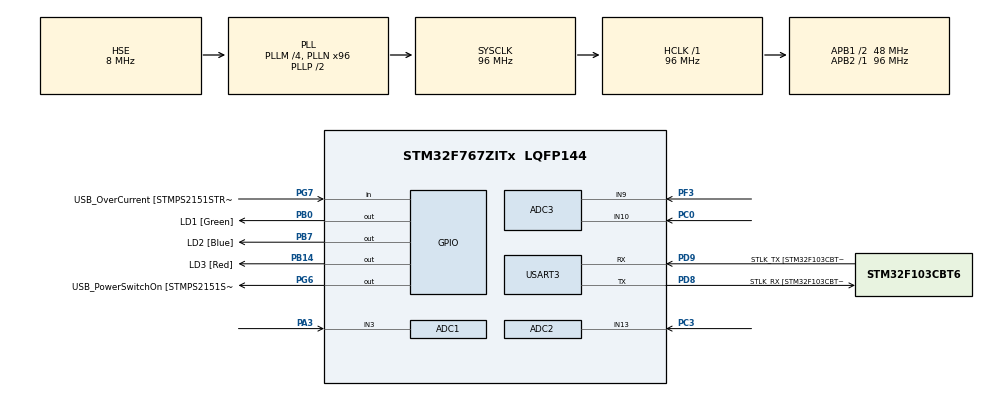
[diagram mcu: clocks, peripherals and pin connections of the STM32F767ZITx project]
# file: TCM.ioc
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ADC1.Channel-0\#ChannelRegularConversion=ADC_CHANNEL_3
ADC1.ContinuousConvMode=ENABLE
ADC1.EOCSelection=ADC_EOC_SEQ_CONV
ADC1.NbrOfConversionFlag=1
ADC1.Rank-0\#ChannelRegularConversion=1
ADC1.SamplingTime-0\#ChannelRegularConversion=ADC_SAMPLETIME_3CYCLES
ADC1.master=1
ADC2.Channel-2\#ChannelRegularConversion=ADC_CHANNEL_13
ADC2.ContinuousConvMode=ENABLE
ADC2.EOCSelection=ADC_EOC_SEQ_CONV
ADC2.NbrOfConversionFlag=1
ADC2.Rank-2\#ChannelRegularConversion=1
ADC2.SamplingTime-2\#ChannelRegularConversion=ADC_SAMPLETIME_3CYCLES
ADC3.Channel-0\#ChannelRegularConversion=ADC_CHANNEL_9
ADC3.ContinuousConvMode=ENABLE
ADC3.EOCSelection=ADC_EOC_SEQ_CONV
ADC3.NbrOfConversionFlag=1
ADC3.Rank-0\#ChannelRegularConversion=1
ADC3.SamplingTime-0\#ChannelRegularConversion=ADC_SAMPLETIME_3CYCLES
FREERTOS.Tasks01=defaultTask,24,256,StartDefaultTask,Default,NULL,Dynamic,NULL,NULL;myTask02,8,256,Comm_Rx_Task,Default,NULL,Dynamic,NULL,NULL;myTask03,8,256,Comm_Tx_Task,Default,NULL,Dynamic,NULL,NULL;myTask04,8,256,TCM_logic_Task,Default,NULL,Dynamic,NULL,NULL;myTask05,8,256,TCM_task,Default,NULL,Dynamic,NULL,NULL
FREERTOS.configUSE_NEWLIB_REENTRANT=1
Mcu.Family=STM32F7
Mcu.Name=STM32F767ZITx
Mcu.Package=LQFP144
NVIC.PriorityGroup=NVIC_PRIORITYGROUP_4
NVIC.TIM1_UP_TIM10_IRQn=true\:15\:0\:false\:false\:true\:false\:false\:true\:true
NVIC.TimeBase=TIM1_UP_TIM10_IRQn
NVIC.TimeBaseIP=TIM1
PA3.Signal=SharedAnalog_PA3
PB0.GPIO_Label=LD1 [Green]
PB0.Signal=GPIO_Output
PB14.GPIO_Label=LD3 [Red]
PB14.Signal=GPIO_Output
PB7.GPIO_Label=LD2 [Blue]
PB7.Signal=GPIO_Output
PC0.Signal=SharedAnalog_PC0
PC14/OSC32_IN.Mode=LSE-External-Oscillator
PC14/OSC32_IN.Signal=RCC_OSC32_IN
PC15/OSC32_OUT.Mode=LSE-External-Oscillator
PC15/OSC32_OUT.Signal=RCC_OSC32_OUT
PC3.Signal=SharedAnalog_PC3
PD8.GPIO_Label=STLK_RX [STM32F103CBT6_PA3]
PD8.Mode=Asynchronous
PD8.Signal=USART3_TX
PD9.GPIO_Label=STLK_TX [STM32F103CBT6_PA2]
PD9.Mode=Asynchronous
PD9.Signal=USART3_RX
PF3.Signal=SharedAnalog_PF3
PG6.GPIO_Label=USB_PowerSwitchOn [STMPS2151STR_EN]
PG6.Signal=GPIO_Output
PG7.GPIO_Label=USB_OverCurrent [STMPS2151STR_FAULT]
PG7.Signal=GPIO_Input
PH0/OSC_IN.GPIO_Label=MCO [STM32F103CBT6_PA8]
PH0/OSC_IN.Mode=HSE-External-Clock-Source
PH0/OSC_IN.Signal=RCC_OSC_IN
PH1/OSC_OUT.Mode=HSE-External-Clock-Source
PH1/OSC_OUT.Signal=RCC_OSC_OUT
ProjectManager.HeapSize=0x200
ProjectManager.StackSize=0x400
ProjectManager.TargetToolchain=STM32CubeIDE
RCC.48MHZClocksFreq_Value=24000000
RCC.AHBFreq_Value=96000000
RCC.APB1CLKDivider=RCC_HCLK_DIV2
RCC.APB1Freq_Value=48000000
RCC.APB1TimFreq_Value=96000000
RCC.APB2Freq_Value=96000000
RCC.APB2TimFreq_Value=96000000
RCC.CortexFreq_Value=96000000
RCC.HCLKFreq_Value=96000000
RCC.HSE_VALUE=8000000
RCC.HSI_VALUE=16000000
RCC.PLLM=4
RCC.PLLMUL=RCC_PLL_MUL9
RCC.PLLN=96
RCC.PLLQ=4
RCC.PLLSourceVirtual=RCC_PLLSOURCE_HSE
RCC.PRESCALERUSB=RCC_USBCLKSOURCE_PLL_DIV1_5
RCC.SYSCLKFreq_VALUE=96000000
RCC.SYSCLKSource=RCC_SYSCLKSOURCE_PLLCLK
RCC.SYSCLKSourceVirtual=RCC_SYSCLKSOURCE_PLLCLK
RCC.USBFreq_Value=48000000
RCC.VCOOutputFreq_Value=192000000
SH.SharedAnalog_PA3.0=GPIO_Analog
SH.SharedAnalog_PA3.1=ADC1_IN3,IN3
SH.SharedAnalog_PC0.0=GPIO_Analog
SH.SharedAnalog_PC0.1=ADC3_IN10,IN10
SH.SharedAnalog_PC3.0=GPIO_Analog
SH.SharedAnalog_PC3.1=ADC2_IN13,IN13
SH.SharedAnalog_PF3.0=GPIO_Analog
SH.SharedAnalog_PF3.1=ADC3_IN9,IN9
USART3.VirtualMode-Asynchronous=VM_ASYNC
VP_FREERTOS_VS_CMSIS_V2.Mode=CMSIS_V2
VP_SYS_VS_tim1.Mode=TIM1
board=NUCLEO-F767ZI

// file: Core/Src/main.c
/* USER CODE BEGIN Header */
/**
  ******************************************************************************
  * @file           : main.c
  * @brief          : Main program body
  ******************************************************************************
  * @attention
  *
  * Copyright (c) 2025 STMicroelectronics.
  * All rights reserved.
  *
  * This software is licensed under terms that can be found in the LICENSE file
  * in the root directory of this software component.
  * If no LICENSE file comes with this software, it is provided AS-IS.
  *
  ******************************************************************************
  */
/* USER CODE END Header */
#include "main.h"
#include "cmsis_os.h"
#include "adc.h"
#include "usart.h"
#include "gpio.h"

/* USER CODE BEGIN Includes */
#include "Rte.h"
/* USER CODE END Includes */

void SystemClock_Config(void);
void MX_FREERTOS_Init(void);

int main(void)
{

  /* MCU Configuration--------------------------------------------------------*/

  /* Reset of all peripherals, Initializes the Flash interface and the Systick. */
  HAL_Init();

  /* Configure the system clock */
  SystemClock_Config();

  /* Initialize all configured peripherals */
  MX_GPIO_Init();
  MX_USART3_UART_Init();
  MX_ADC1_Init();
  MX_ADC2_Init();
  MX_ADC3_Init();

  /* Init scheduler */
  osKernelInitialize();  /* Call init function for freertos objects (in cmsis_os2.c) */
  MX_FREERTOS_Init();

  /* Start scheduler */
  osKernelStart();

  /* We should never get here as control is now taken by the scheduler */

  /* Infinite loop */
  while (1)
  {

  }
}

void SystemClock_Config(void)
{
  RCC_OscInitTypeDef RCC_OscInitStruct = {0};
  RCC_ClkInitTypeDef RCC_ClkInitStruct = {0};

  /** Configure LSE Drive Capability
  */
  HAL_PWR_EnableBkUpAccess();

  /** Configure the main internal regulator output voltage
  */
  __HAL_RCC_PWR_CLK_ENABLE();
  __HAL_PWR_VOLTAGESCALING_CONFIG(PWR_REGULATOR_VOLTAGE_SCALE3);

  /** Initializes the RCC Oscillators according to the specified parameters
  * in the RCC_OscInitTypeDef structure.
  */
  RCC_OscInitStruct.OscillatorType = RCC_OSCILLATORTYPE_HSE;
  RCC_OscInitStruct.HSEState = RCC_HSE_BYPASS;
  RCC_OscInitStruct.PLL.PLLState = RCC_PLL_ON;
  RCC_OscInitStruct.PLL.PLLSource = RCC_PLLSOURCE_HSE;
  RCC_OscInitStruct.PLL.PLLM = 4;
  RCC_OscInitStruct.PLL.PLLN = 96;
  RCC_OscInitStruct.PLL.PLLP = RCC_PLLP_DIV2;
  RCC_OscInitStruct.PLL.PLLQ = 4;
  RCC_OscInitStruct.PLL.PLLR = 2;
  if (HAL_RCC_OscConfig(&RCC_OscInitStruct) != HAL_OK)
  {
    Error_Handler();
  }

  /** Activate the Over-Drive mode
  */
  if (HAL_PWREx_EnableOverDrive() != HAL_OK)
  {
    Error_Handler();
  }

  /** Initializes the CPU, AHB and APB buses clocks
  */
  RCC_ClkInitStruct.ClockType = RCC_CLOCKTYPE_HCLK|RCC_CLOCKTYPE_SYSCLK
                              |RCC_CLOCKTYPE_PCLK1|RCC_CLOCKTYPE_PCLK2;
  RCC_ClkInitStruct.SYSCLKSource = RCC_SYSCLKSOURCE_PLLCLK;
  RCC_ClkInitStruct.AHBCLKDivider = RCC_SYSCLK_DIV1;
  RCC_ClkInitStruct.APB1CLKDivider = RCC_HCLK_DIV2;
  RCC_ClkInitStruct.APB2CLKDivider = RCC_HCLK_DIV1;

  if (HAL_RCC_ClockConfig(&RCC_ClkInitStruct, FLASH_LATENCY_3) != HAL_OK)
  {
    Error_Handler();
  }
}

void HAL_TIM_PeriodElapsedCallback(TIM_HandleTypeDef *htim)
{
  if (htim->Instance == TIM1)
  {
    HAL_IncTick();
  }
}

void Error_Handler(void)
{
  __disable_irq();
  while (1)
  {
  }
}

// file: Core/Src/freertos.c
/* USER CODE BEGIN Header */
/**
  ******************************************************************************
  * File Name          : freertos.c
  * Description        : Code for freertos applications
  ******************************************************************************
  * @attention
  *
  * Copyright (c) 2025 STMicroelectronics.
  * All rights reserved.
  *
  * This software is licensed under terms that can be found in the LICENSE file
  * in the root directory of this software component.
  * If no LICENSE file comes with this software, it is provided AS-IS.
  *
  ******************************************************************************
  */
/* USER CODE END Header */

#include "FreeRTOS.h"
#include "task.h"
#include "main.h"
#include "cmsis_os.h"

/* USER CODE BEGIN Includes */
#include "gpio.h"
/* USER CODE END Includes */

/* Definitions for defaultTask */
osThreadId_t defaultTaskHandle;
const osThreadAttr_t defaultTask_attributes = {
  .name = "defaultTask",
  .stack_size = 256 * 4,
  .priority = (osPriority_t) osPriorityNormal,
};
/* Definitions for myTask02 */
osThreadId_t myTask02Handle;
const osThreadAttr_t myTask02_attributes = {
  .name = "myTask02",
  .stack_size = 256 * 4,
  .priority = (osPriority_t) osPriorityLow,
};
/* Definitions for myTask03 */
osThreadId_t myTask03Handle;
const osThreadAttr_t myTask03_attributes = {
  .name = "myTask03",
  .stack_size = 256 * 4,
  .priority = (osPriority_t) osPriorityLow,
};
/* Definitions for myTask04 */
osThreadId_t myTask04Handle;
const osThreadAttr_t myTask04_attributes = {
  .name = "myTask04",
  .stack_size = 256 * 4,
  .priority = (osPriority_t) osPriorityLow,
};
/* Definitions for myTask05 */
osThreadId_t myTask05Handle;
const osThreadAttr_t myTask05_attributes = {
  .name = "myTask05",
  .stack_size = 256 * 4,
  .priority = (osPriority_t) osPriorityLow,
};

void StartDefaultTask(void *argument);
void Comm_Rx_Task(void *argument);
void Comm_Tx_Task(void *argument);
void TCM_logic_Task(void *argument);
void TCM_task(void *argument);

void MX_FREERTOS_Init(void); /* (MISRA C 2004 rule 8.1) */

void MX_FREERTOS_Init(void) {

  /* Create the thread(s) */
  /* creation of defaultTask */
  defaultTaskHandle = osThreadNew(StartDefaultTask, NULL, &defaultTask_attributes);

  /* creation of myTask02 */
  myTask02Handle = osThreadNew(Comm_Rx_Task, NULL, &myTask02_attributes);

  /* creation of myTask03 */
  myTask03Handle = osThreadNew(Comm_Tx_Task, NULL, &myTask03_attributes);

  /* creation of myTask04 */
  myTask04Handle = osThreadNew(TCM_logic_Task, NULL, &myTask04_attributes);

  /* creation of myTask05 */
  myTask05Handle = osThreadNew(TCM_task, NULL, &myTask05_attributes);

}

void StartDefaultTask(void *argument)
{
  /* USER CODE BEGIN StartDefaultTask */
  /* Infinite loop */
  for(;;)
  {
	HAL_GPIO_WritePin(LD3_GPIO_Port, LD3_Pin, GPIO_PIN_SET);   // LED Rojo ON
	HAL_GPIO_WritePin(LD2_GPIO_Port, LD2_Pin, GPIO_PIN_RESET); // LED Azul OFF
	HAL_GPIO_WritePin(LD1_GPIO_Port, LD1_Pin, GPIO_PIN_RESET); // LED Verde OFF
	HAL_Delay(1000);

	HAL_GPIO_WritePin(LD3_GPIO_Port, LD3_Pin, GPIO_PIN_RESET); // LED Rojo OFF
	HAL_GPIO_WritePin(LD2_GPIO_Port, LD2_Pin, GPIO_PIN_SET); // LED Azul ON
	HAL_GPIO_WritePin(LD1_GPIO_Port, LD1_Pin, GPIO_PIN_RESET);   // LED Verde OFF
	HAL_Delay(1000);

	HAL_GPIO_WritePin(LD3_GPIO_Port, LD3_Pin, GPIO_PIN_RESET); // LED Rojo OFF
	HAL_GPIO_WritePin(LD2_GPIO_Port, LD2_Pin, GPIO_PIN_RESET); // LED Azul OFF
	HAL_GPIO_WritePin(LD1_GPIO_Port, LD1_Pin, GPIO_PIN_SET);   // LED Verde ON
	HAL_Delay(1000);
  }
  /* USER CODE END StartDefaultTask */
}

void Comm_Rx_Task(void *argument)
{
  for(;;)
  {
    osDelay(1);
  }
}

void Comm_Tx_Task(void *argument)
{
  for(;;)
  {
    osDelay(1);
  }
}

void TCM_logic_Task(void *argument)
{
  for(;;)
  {
    osDelay(1);
  }
}

void TCM_task(void *argument)
{
  for(;;)
  {
    osDelay(1);
  }
}
